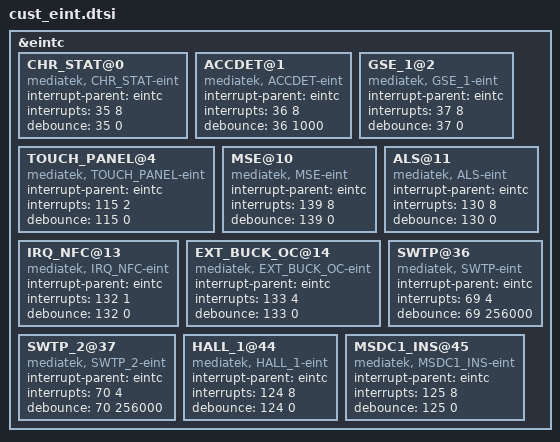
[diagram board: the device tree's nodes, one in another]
/*
 * Generated by MTK SP DrvGen Version 03.13.6 for MT6752. Copyright MediaTek Inc. (C) 2013.
 * Mon Dec 25 10:49:56 2017
 * Do Not Modify the File.
 */

/*************************
 * EINT DTSI File
*************************/

&eintc {
	CHR_STAT@0 {
		compatible = "mediatek, CHR_STAT-eint";
		interrupt-parent = <&eintc>;
		interrupts = <35 8>;
		debounce = <35 0>;
	};

	ACCDET@1 {
		compatible = "mediatek, ACCDET-eint";
		interrupt-parent = <&eintc>;
		interrupts = <36 8>;
		debounce = <36 1000>;
	};

	GSE_1@2 {
		compatible = "mediatek, GSE_1-eint";
		interrupt-parent = <&eintc>;
		interrupts = <37 8>;
		debounce = <37 0>;
	};

	TOUCH_PANEL@4 {
		compatible = "mediatek, TOUCH_PANEL-eint";
		interrupt-parent = <&eintc>;
		interrupts = <115 2>;
		debounce = <115 0>;
	};

	MSE@10 {
		compatible = "mediatek, MSE-eint";
		interrupt-parent = <&eintc>;
		interrupts = <139 8>;
		debounce = <139 0>;
	};

	ALS@11 {
		compatible = "mediatek, ALS-eint";
		interrupt-parent = <&eintc>;
		interrupts = <130 8>;
		debounce = <130 0>;
	};

	IRQ_NFC@13 {
		compatible = "mediatek, IRQ_NFC-eint";
		interrupt-parent = <&eintc>;
		interrupts = <132 1>;
		debounce = <132 0>;
	};

	EXT_BUCK_OC@14 {
		compatible = "mediatek, EXT_BUCK_OC-eint";
		interrupt-parent = <&eintc>;
		interrupts = <133 4>;
		debounce = <133 0>;
	};

	SWTP@36 {
		compatible = "mediatek, SWTP-eint";
		interrupt-parent = <&eintc>;
		interrupts = <69 4>;
		debounce = <69 256000>;
	};

	SWTP_2@37 {
		compatible = "mediatek, SWTP_2-eint";
		interrupt-parent = <&eintc>;
		interrupts = <70 4>;
		debounce = <70 256000>;
	};

	HALL_1@44 {
		compatible = "mediatek, HALL_1-eint";
		interrupt-parent = <&eintc>;
		interrupts = <124 8>;
		debounce = <124 0>;
	};

	MSDC1_INS@45 {
		compatible = "mediatek, MSDC1_INS-eint";
		interrupt-parent = <&eintc>;
		interrupts = <125 8>;
		debounce = <125 0>;
	};

};
